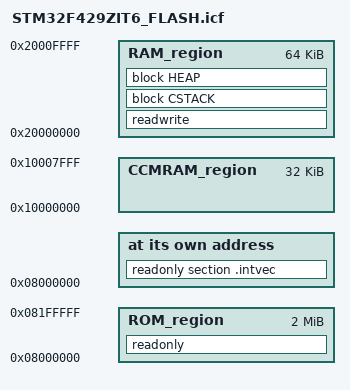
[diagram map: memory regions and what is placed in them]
/* IAR Linker Configuration File for STM32F429ZIT6 */

define symbol __ICFEDIT_intvec_start__ = 0x08000000;
define symbol __ICFEDIT_region_ROM_start__ = 0x08000000;
define symbol __ICFEDIT_region_ROM_end__   = 0x081FFFFF;
define symbol __ICFEDIT_region_RAM_start__ = 0x20000000;
define symbol __ICFEDIT_region_RAM_end__   = 0x2000FFFF;
define symbol __ICFEDIT_region_CCMRAM_start__ = 0x10000000;
define symbol __ICFEDIT_region_CCMRAM_end__   = 0x10007FFF;

define symbol __ICFEDIT_size_cstack__ = 0x400;
define symbol __ICFEDIT_size_heap__   = 0x200;

define memory region with size = {__ICFEDIT_region_ROM_end__ - __ICFEDIT_region_ROM_start__ + 1};
define memory region with size = {__ICFEDIT_region_RAM_end__ - __ICFEDIT_region_RAM_start__ + 1};
define memory region with size = {__ICFEDIT_region_CCMRAM_end__ - __ICFEDIT_region_CCMRAM_start__ + 1};

define region ROM_region  = mem:[from __ICFEDIT_region_ROM_start__ to __ICFEDIT_region_ROM_end__];
define region RAM_region  = mem:[from __ICFEDIT_region_RAM_start__ to __ICFEDIT_region_RAM_end__];
define region CCMRAM_region = mem:[from __ICFEDIT_region_CCMRAM_start__ to __ICFEDIT_region_CCMRAM_end__];

define block CSTACK    with size = __ICFEDIT_size_cstack__, alignment = 8 { };
define block HEAP      with size = __ICFEDIT_size_heap__,   alignment = 8 { };

initialize by copy { readwrite };
do not initialize  { section .noinit };

place at address mem:__ICFEDIT_intvec_start__ { readonly section .intvec };
place in ROM_region  { readonly };
place in RAM_region  { readwrite, block CSTACK, block HEAP };
place in CCMRAM_region { };
